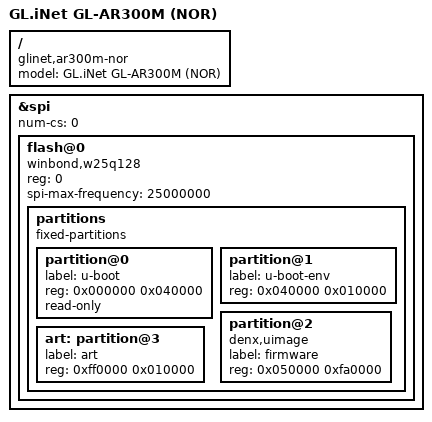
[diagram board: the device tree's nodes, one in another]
/dts-v1/;

#include <dt-bindings/gpio/gpio.h>
#include <dt-bindings/input/input.h>

#include "qca9531_glinet_ar300m.dtsi"

/ {
	compatible = "glinet,ar300m-nor", "qca,qca9531";
	model = "GL.iNet GL-AR300M (NOR)";
};

&spi {
	status = "okay";
	num-cs = <0>;

	flash@0 {
		compatible = "winbond,w25q128", "jedec,spi-nor";
		reg = <0>;
		spi-max-frequency = <25000000>;

		partitions {
			compatible = "fixed-partitions";
			#address-cells = <1>;
			#size-cells = <1>;

			partition@0 {
				label = "u-boot";
				reg = <0x000000 0x040000>;
				read-only;
			};

			partition@1 {
				label = "u-boot-env";
				reg = <0x040000 0x010000>;
			};

			partition@2 {
				compatible = "denx,uimage";
				label = "firmware";
				reg = <0x050000 0xfa0000>;
			};

			art: partition@3 {
				label = "art";
				reg = <0xff0000 0x010000>;
			};
		};
	};
};
